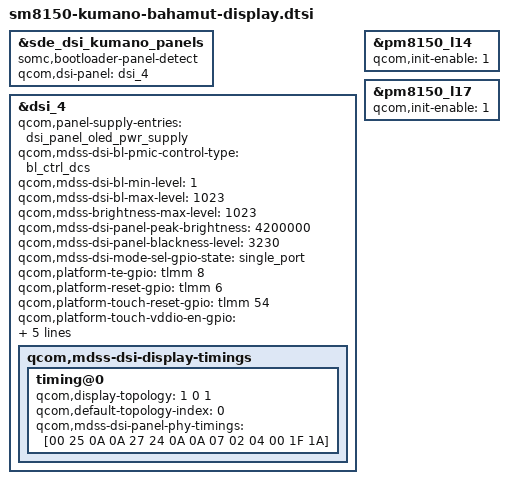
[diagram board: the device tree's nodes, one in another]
/* Copyright (c) 2015-2019, The Linux Foundation. All rights reserved.
 *
 * This program is free software; you can redistribute it and/or modify
 * it under the terms of the GNU General Public License version 2 and
 * only version 2 as published by the Free Software Foundation.
 *
 * This program is distributed in the hope that it will be useful,
 * but WITHOUT ANY WARRANTY; without even the implied warranty of
 * MERCHANTABILITY or FITNESS FOR A PARTICULAR PURPOSE.  See the
 * GNU General Public License for more details.
 */
/*
 * Copyright (C) 2019 Sony Mobile Communications Inc.
 *
 * This program is free software; you can redistribute it and/or modify
 * it under the terms of the GNU General Public License version 2, as
 * published by the Free Software Foundation.
 */
#include "dsi-panel-somc-sec-1080p2520-cmd.dtsi"

&sde_dsi_kumano_panels {
	/* Only one possible panel on PROD SoMC Bahamut */
	somc,bootloader-panel-detect;

	qcom,dsi-panel = <&dsi_4>;
};

&dsi_4 {
	qcom,panel-supply-entries = <&dsi_panel_oled_pwr_supply>;
	/delete-property/ qcom,panel-vspvsn-supply-entries;
	qcom,mdss-dsi-bl-pmic-control-type = "bl_ctrl_dcs";
	qcom,mdss-dsi-bl-min-level = <1>;
	qcom,mdss-dsi-bl-max-level = <1023>;
	qcom,mdss-brightness-max-level = <1023>;
	qcom,mdss-dsi-panel-peak-brightness = <4200000>;
	qcom,mdss-dsi-panel-blackness-level = <3230>;
	qcom,mdss-dsi-mode-sel-gpio-state = "single_port";
	qcom,platform-te-gpio = <&tlmm 8 0>;
	qcom,platform-reset-gpio = <&tlmm 6 0>;
	qcom,platform-touch-reset-gpio = <&tlmm 54 0>;
	qcom,platform-touch-vddio-en-gpio = <&pm8150l_gpios 1 0>;
	qcom,platform-touch-vddh-en-gpio = <&pm8150b_gpios 7 0>;
	somc,disp-err-flag-gpio = <&tlmm 101 0>;

	/* Enable protected HBM range */
	somc,set-hbm-usable;

	qcom,mdss-dsi-display-timings {
		timing@0 {
			qcom,display-topology = <1 0 1>;
			qcom,default-topology-index = <0>;
			qcom,mdss-dsi-panel-phy-timings = [00 25 0A 0A 27 24 0A 0A 07 02 04 00 1F 1A];
		};
	};
};

&pm8150_l14 {
	qcom,init-enable = <1>;
};

&pm8150_l17 {
	qcom,init-enable = <1>;
};

